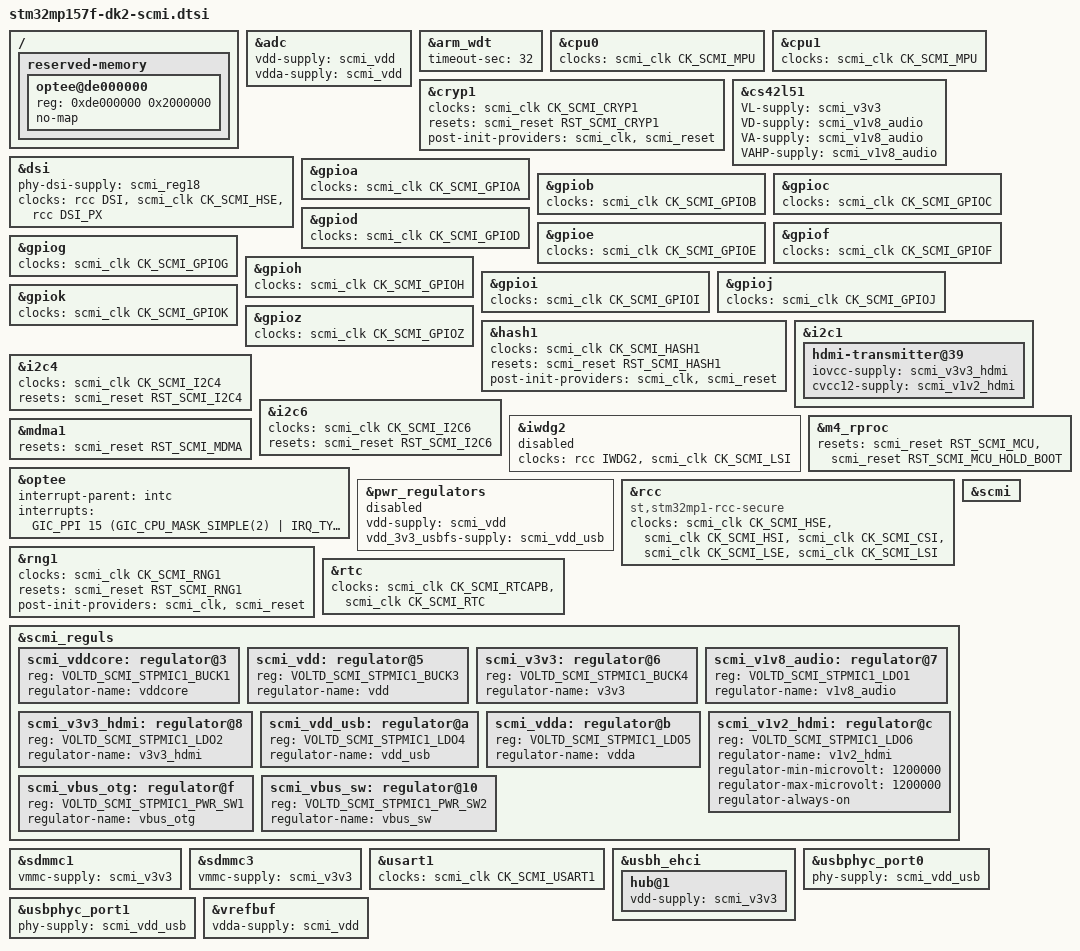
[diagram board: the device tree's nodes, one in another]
// SPDX-License-Identifier: (GPL-2.0-only OR BSD-3-Clause)
/*
 * Copyright (C) STMicroelectronics 2025 - All Rights Reserved
 * Author: Amelie Delaunay <amelie.delaunay@foss.st.com> for STMicroelectronics.
 */

#include "stm32mp15-scmi.dtsi"

/ {
	reserved-memory {
		optee@de000000 {
			reg = <0xde000000 0x2000000>;
			no-map;
		};
	};
};

&adc {
	vdd-supply = <&scmi_vdd>;
	vdda-supply = <&scmi_vdd>;
};

&arm_wdt {
	bootph-all;
	timeout-sec = <32>;
	status = "okay";
};

&cpu0 {
	clocks = <&scmi_clk CK_SCMI_MPU>;
};

&cpu1 {
	clocks = <&scmi_clk CK_SCMI_MPU>;
};

&cryp1 {
	clocks = <&scmi_clk CK_SCMI_CRYP1>;
	resets = <&scmi_reset RST_SCMI_CRYP1>;
	post-init-providers = <&scmi_clk>, <&scmi_reset>;
};

&cs42l51 {
	VL-supply = <&scmi_v3v3>;
	VD-supply = <&scmi_v1v8_audio>;
	VA-supply = <&scmi_v1v8_audio>;
	VAHP-supply = <&scmi_v1v8_audio>;
};

&dsi {
	phy-dsi-supply = <&scmi_reg18>;
	clocks = <&rcc DSI>, <&scmi_clk CK_SCMI_HSE>, <&rcc DSI_PX>;
};

&gpioa {
	clocks = <&scmi_clk CK_SCMI_GPIOA>;
};

&gpiob {
	clocks = <&scmi_clk CK_SCMI_GPIOB>;
};

&gpioc {
	clocks = <&scmi_clk CK_SCMI_GPIOC>;
};

&gpiod {
	clocks = <&scmi_clk CK_SCMI_GPIOD>;
};

&gpioe {
	clocks = <&scmi_clk CK_SCMI_GPIOE>;
};

&gpiof {
	clocks = <&scmi_clk CK_SCMI_GPIOF>;
};

&gpiog {
	clocks = <&scmi_clk CK_SCMI_GPIOG>;
};

&gpioh {
	clocks = <&scmi_clk CK_SCMI_GPIOH>;
};

&gpioi {
	clocks = <&scmi_clk CK_SCMI_GPIOI>;
};

&gpioj {
	clocks = <&scmi_clk CK_SCMI_GPIOJ>;
};

&gpiok {
	clocks = <&scmi_clk CK_SCMI_GPIOK>;
};

&gpioz {
	clocks = <&scmi_clk CK_SCMI_GPIOZ>;
};

&hash1 {
	clocks = <&scmi_clk CK_SCMI_HASH1>;
	resets = <&scmi_reset RST_SCMI_HASH1>;
	post-init-providers = <&scmi_clk>, <&scmi_reset>;
};

&i2c1 {
	hdmi-transmitter@39 {
		iovcc-supply = <&scmi_v3v3_hdmi>;
		cvcc12-supply = <&scmi_v1v2_hdmi>;
	};
};

&i2c4 {
	clocks = <&scmi_clk CK_SCMI_I2C4>;
	resets = <&scmi_reset RST_SCMI_I2C4>;
};

&i2c6 {
	clocks = <&scmi_clk CK_SCMI_I2C6>;
	resets = <&scmi_reset RST_SCMI_I2C6>;
};

&iwdg2 {
	clocks = <&rcc IWDG2>, <&scmi_clk CK_SCMI_LSI>;
	status = "disabled";
};

&m4_rproc {
	/delete-property/ st,syscfg-holdboot;
	resets = <&scmi_reset RST_SCMI_MCU>,
		 <&scmi_reset RST_SCMI_MCU_HOLD_BOOT>;
	reset-names = "mcu_rst", "hold_boot";
};

&mdma1 {
	resets = <&scmi_reset RST_SCMI_MDMA>;
};

&optee {
	interrupt-parent = <&intc>;
	interrupts = <GIC_PPI 15 (GIC_CPU_MASK_SIMPLE(2) | IRQ_TYPE_LEVEL_LOW)>;
	bootph-some-ram;
};

&pwr_regulators {
	vdd-supply = <&scmi_vdd>;
	vdd_3v3_usbfs-supply = <&scmi_vdd_usb>;
	status = "disabled";
};

&rcc {
	compatible = "st,stm32mp1-rcc-secure", "syscon";
	clock-names = "hse", "hsi", "csi", "lse", "lsi";
	clocks = <&scmi_clk CK_SCMI_HSE>,
		 <&scmi_clk CK_SCMI_HSI>,
		 <&scmi_clk CK_SCMI_CSI>,
		 <&scmi_clk CK_SCMI_LSE>,
		 <&scmi_clk CK_SCMI_LSI>;
};

&rng1 {
	clocks = <&scmi_clk CK_SCMI_RNG1>;
	resets = <&scmi_reset RST_SCMI_RNG1>;
	post-init-providers = <&scmi_clk>, <&scmi_reset>;
};

&rtc {
	clocks = <&scmi_clk CK_SCMI_RTCAPB>, <&scmi_clk CK_SCMI_RTC>;
};

&scmi {
	bootph-some-ram;
};

&scmi_reguls {
	scmi_vddcore: regulator@3 {
		reg = <VOLTD_SCMI_STPMIC1_BUCK1>;
		regulator-name = "vddcore";
	};

	scmi_vdd: regulator@5 {
		reg = <VOLTD_SCMI_STPMIC1_BUCK3>;
		regulator-name = "vdd";
	};

	scmi_v3v3: regulator@6 {
		reg = <VOLTD_SCMI_STPMIC1_BUCK4>;
		regulator-name = "v3v3";
	};

	scmi_v1v8_audio: regulator@7 {
		reg = <VOLTD_SCMI_STPMIC1_LDO1>;
		regulator-name = "v1v8_audio";
	};

	scmi_v3v3_hdmi: regulator@8 {
		reg = <VOLTD_SCMI_STPMIC1_LDO2>;
		regulator-name = "v3v3_hdmi";
	};

	scmi_vdd_usb: regulator@a {
		reg = <VOLTD_SCMI_STPMIC1_LDO4>;
		regulator-name = "vdd_usb";
	};

	scmi_vdda: regulator@b {
		reg = <VOLTD_SCMI_STPMIC1_LDO5>;
		regulator-name = "vdda";
	};

	scmi_v1v2_hdmi: regulator@c {
		reg = <VOLTD_SCMI_STPMIC1_LDO6>;
		regulator-name = "v1v2_hdmi";
		regulator-min-microvolt = <1200000>;
		regulator-max-microvolt = <1200000>;
		regulator-always-on;
	};

	scmi_vbus_otg: regulator@f {
		reg = <VOLTD_SCMI_STPMIC1_PWR_SW1>;
		regulator-name = "vbus_otg";
	 };

	 scmi_vbus_sw: regulator@10 {
		reg = <VOLTD_SCMI_STPMIC1_PWR_SW2>;
		regulator-name = "vbus_sw";
	 };
};

&sdmmc1 {
	vmmc-supply = <&scmi_v3v3>;
};

&sdmmc3 {
	vmmc-supply = <&scmi_v3v3>;
};

&usart1 {
	clocks = <&scmi_clk CK_SCMI_USART1>;
};

&usbh_ehci {
	hub@1 {
		vdd-supply = <&scmi_v3v3>;
	};
};

&usbphyc_port0 {
	phy-supply = <&scmi_vdd_usb>;
};

&usbphyc_port1 {
	phy-supply = <&scmi_vdd_usb>;
};

&vrefbuf {
	vdda-supply = <&scmi_vdd>;
};
